# MIMXRT1062 register map
Vendor: nxp.com; File version: 1.0
CPU: CM7 r0p1, little endian, MPU, FPU, VTOR, 4 interrupt priority bits
Registers are 32-bit, read-write, reset 0x0 unless marked. A register's access mark holds for its fields unless they carry their own. Offsets are from the block's base; [hi:lo] are bit positions; {n}, {i} and the like mark numbered series; 'fields as' and 'values as' point back to an identical list.

## PGC
Base 0x400F4000; register names take the prefix PGC_; alternate view of GPC
0x220 MEGA_CTRL — PGC Mega Control Register
  [0] PCR — Power Control PCR must not change from power-down request (pdn_req) assertion until the target subsystem is completely powered up
    0=Do not switch off power even if pdn_req is asserted; 1=Switch off power when pdn_req is asserted
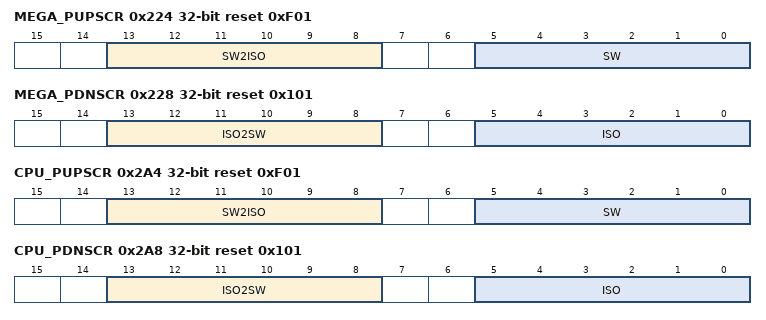
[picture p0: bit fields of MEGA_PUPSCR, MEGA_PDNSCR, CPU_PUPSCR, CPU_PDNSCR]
0x224 MEGA_PUPSCR reset 0xF01 — PGC Mega Power Up Sequence Control Register
  [13:8] SW2ISO — After asserting power toggle on/off signal (switch_b), the PGC waits a number of IPG clocks equal to the value of SW2ISO before negating isolation
  [5:0] SW — After a power-up request (pup_req assertion), the PGC waits a number of IPG clocks equal to the value of SW before asserting power toggle on/off signal (switch_b)
0x228 MEGA_PDNSCR reset 0x101 — PGC Mega Pull Down Sequence Control Register
  [13:8] ISO2SW — After asserting isolation, the PGC waits a number of IPG clocks equal to the value of ISO2SW before negating power toggle on/off signal (switch_b)
  [5:0] ISO — After a power-down request (pdn_req assertion), the PGC waits a number of IPG clocks equal to the value of ISO before asserting isolation
0x22C MEGA_SR — PGC Mega Power Gating Controller Status Register
  [0] PSR — Power status
    0=The target subsystem was not powered down for the previous power-down request; 1=The target subsystem was powered down for the previous power-down request
0x2A0 CPU_CTRL — PGC CPU Control Register
  fields as MEGA_CTRL
0x2A4 CPU_PUPSCR reset 0xF01 — PGC CPU Power Up Sequence Control Register
  [13:8] SW2ISO — There are two different silicon revisions: 1
  [5:0] SW — There are two different silicon revisions: 1
0x2A8 CPU_PDNSCR reset 0x101 — PGC CPU Pull Down Sequence Control Register
  [13:8] ISO2SW — After asserting isolation, the PGC waits a number of 32k clocks equal to the value of ISO2SW before negating
  [5:0] ISO — After a power-down request (pdn_req assertion), the PGC waits a number of 32k clocks equal to the value of ISO before asserting isolation
0x2AC CPU_SR — PGC CPU Power Gating Controller Status Register
  fields as MEGA_SR

## ROMC
Base 0x40180000; register names take the prefix ROMC_
0xD4 ROMPATCH{x}D (x=7,6,5,4,3,2,1,0; step 0x4) — ROMC Data Registers
  [31:0] DATAX — Data Fix Registers - Stores the data used for 1-word data fix operations
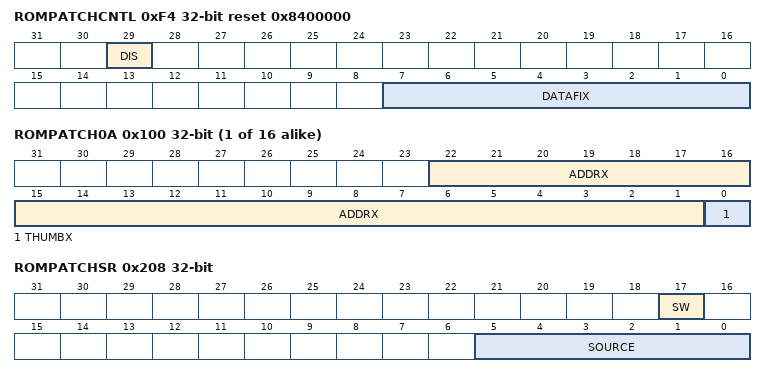
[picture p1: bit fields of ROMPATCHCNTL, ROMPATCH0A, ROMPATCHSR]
0xF4 ROMPATCHCNTL reset 0x8400000 — ROMC Control Register
  [29] DIS — ROMC Disable -- This bit, when set, disables all ROMC operations
    0=Does not affect any ROMC functions (default); 1=Disable all ROMC functions: data fixing, and opcode patching
  [7:0] DATAFIX — Data Fix Enable - Controls the use of the first 8 address comparators for 1-word data fix or for code patch routine
    0=Address comparator triggers a opcode patch; 1=Address comparator triggers a data fix
0xF8 ROMPATCHENH ro — ROMC Enable Register High
0xFC ROMPATCHENL — ROMC Enable Register Low
  [15:0] ENABLE — Enable Address Comparator - This bit enables the corresponding address comparator to trigger an event
    0=Address comparator disabled; 1=Address comparator enabled, ROMC will trigger a opcode patch or data fix event upon matching of the associated address
{0x100+4i} ROMPATCH{i}A (i=0..15) — ROMC Address Registers
  [22:1] ADDRX — Address Comparator Registers - Indicates the memory address to be watched
  [0] THUMBX — THUMB Comparator Select - Indicates that this address will trigger a THUMB opcode patch or an Arm opcode patch
    0=Arm patch; 1=THUMB patch (ignore if data fix)
0x208 ROMPATCHSR — ROMC Status Register
  [17] SW write-1-clears — ROMC AHB Multiple Address Comparator matches Indicator - Indicates that multiple address comparator matches occurred
    0=no event or comparator collisions; 1=a collision has occurred
  [5:0] SOURCE ro — ROMC Source Number - Binary encoding of the number of the address comparator which has an address match in the most recent patch event on ROMC AHB
    0=Address Comparator 0 matched; 1=Address Comparator 1 matched; 15=Address Comparator 15 matched
